# DEMOCHIP register map
File version: 1.0
Demo device for regdrift
Registers are 32-bit, read-write, reset 0x0 unless marked. A register's access mark holds for its fields unless they carry their own. Offsets are from the block's base; lines under a group give offsets from that group; [hi:lo] are bit positions; {n}, {i} and the like mark numbered series; 'fields as' and 'values as' point back to an identical list; <NAME> marks a mode.

## Memory map
0x40040000 ACCEL — Matrix accelerator control block

## Interrupts
17 ACCEL_DONE (ACCEL)

## ACCEL — Matrix accelerator control block
Base 0x40040000
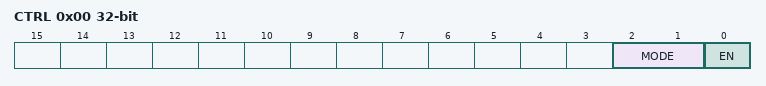
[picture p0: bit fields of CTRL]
0x00 CTRL — Control
  [2:1] MODE, [0] EN
0x08 STATUS reset 0x1 — Status flags
  [0] DONE write-1-clears
